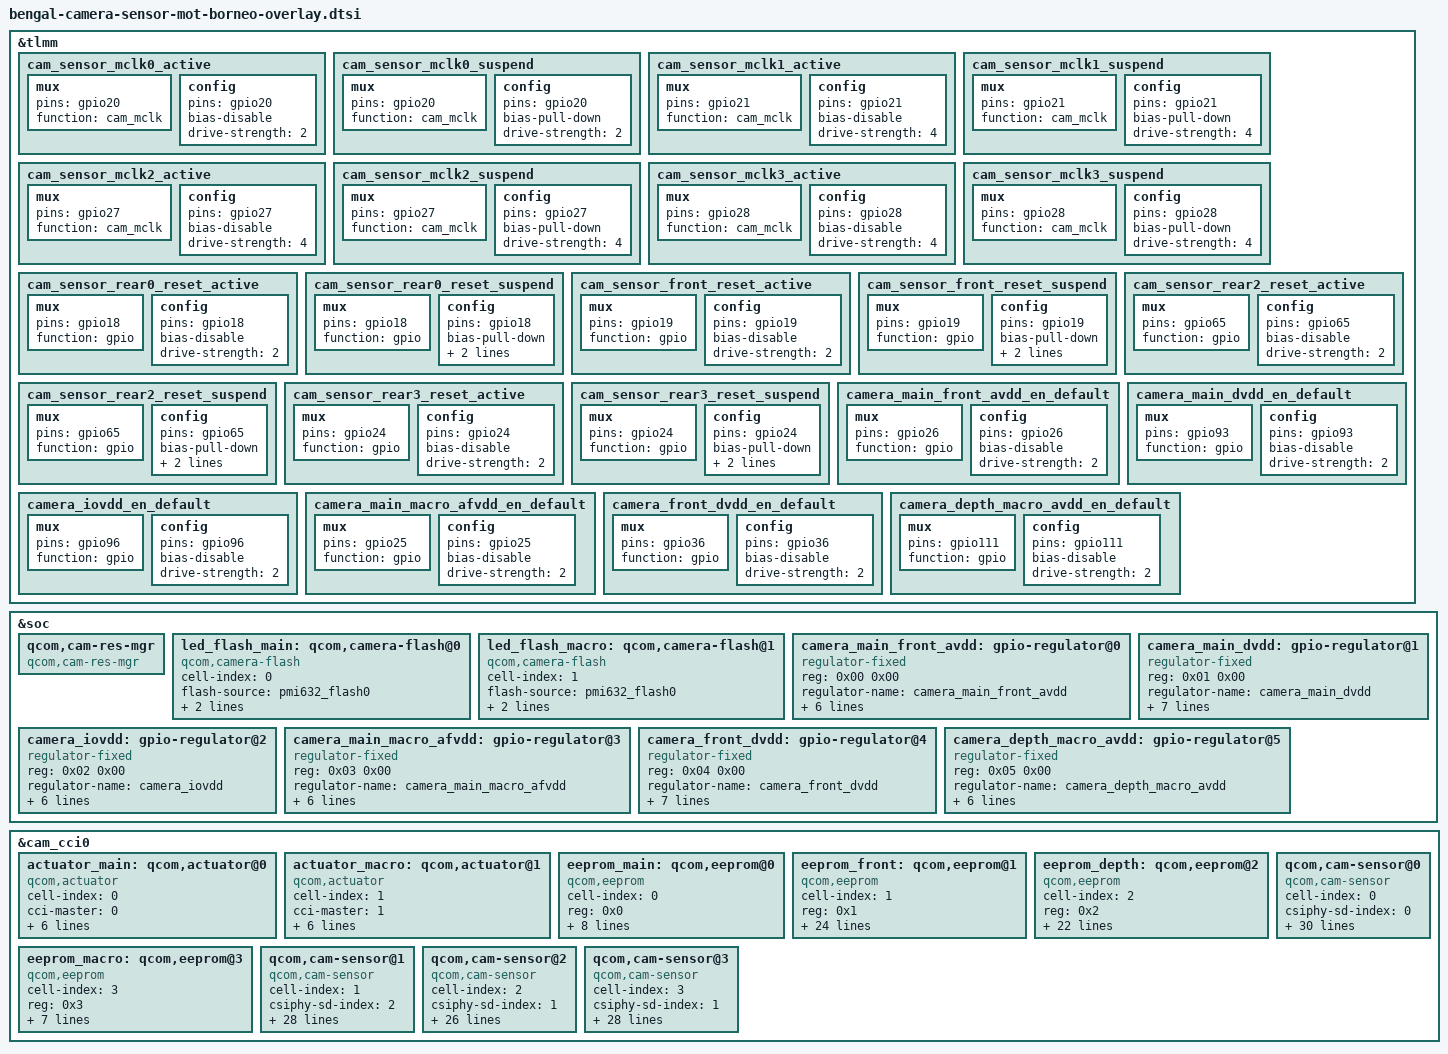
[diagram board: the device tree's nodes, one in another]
#include <dt-bindings/clock/qcom,gcc-bengal.h>

&tlmm {
	cam_sensor_mclk0_active: cam_sensor_mclk0_active {
		/* main mclk*/
		mux {
			pins = "gpio20";
			function = "cam_mclk";
		};

		config {
			pins = "gpio20";
			bias-disable;
			drive-strength = <2>;
		};
	};

	cam_sensor_mclk0_suspend: cam_sensor_mclk0_suspend {
		/* main mclk*/
		mux {
			pins = "gpio20";
			function = "cam_mclk";
		};

		config {
			pins = "gpio20";
			bias-pull-down;
			drive-strength = <2>;
		};
	};

	cam_sensor_mclk1_active: cam_sensor_mclk1_active {
		/* front mclk*/
		mux {
			pins = "gpio21";
			function = "cam_mclk";
		};

		config {
			pins = "gpio21";
			bias-disable;
			drive-strength = <4>;
		};
	};

	cam_sensor_mclk1_suspend: cam_sensor_mclk1_suspend {
		/* front mclk*/
		mux {
			pins = "gpio21";
			function = "cam_mclk";
		};

		config {
			pins = "gpio21";
			bias-pull-down;
			drive-strength = <4>;
		};
	};

	cam_sensor_mclk2_active: cam_sensor_mclk2_active {
		/* macro mclk*/
		mux {
			pins = "gpio27";
			function = "cam_mclk";
		};

		config {
			pins = "gpio27";
			bias-disable;
			drive-strength = <4>;
		};
	};

	cam_sensor_mclk2_suspend: cam_sensor_mclk2_suspend {
		/* macro mclk*/
		mux {
			pins = "gpio27";
			function = "cam_mclk";
		};

		config {
			pins = "gpio27";
			bias-pull-down;
			drive-strength = <4>;
		};
	};

	cam_sensor_mclk3_active: cam_sensor_mclk3_active {
		/* depth mclk*/
		mux {
			pins = "gpio28";
			function = "cam_mclk";
		};

		config {
			pins = "gpio28";
			bias-disable;
			drive-strength = <4>;
		};
	};

	cam_sensor_mclk3_suspend: cam_sensor_mclk3_suspend {
		/* depth mclk*/
		mux {
			pins = "gpio28";
			function = "cam_mclk";
		};

		config {
			pins = "gpio28";
			bias-pull-down;
			drive-strength = <4>;
		};
	};

	cam_sensor_rear0_reset_active: cam_sensor_rear0_reset_active {
		/* main reset*/
		mux {
			pins = "gpio18";
			function = "gpio";
		};

		config {
			pins = "gpio18";
			bias-disable; /* No PULL */
			drive-strength = <2>;
		};
	};

	cam_sensor_rear0_reset_suspend: cam_sensor_rear0_reset_suspend {
		/* main reset*/
		mux {
			pins = "gpio18";
			function = "gpio";
		};

		config {
			pins = "gpio18";
			bias-pull-down; /* PULL DOWN */
			drive-strength = <2>;
			output-low;
		};
	};

	cam_sensor_front_reset_active: cam_sensor_front_reset_active {
		/* front reset*/
		mux {
			pins = "gpio19";
			function = "gpio";
		};

		config {
			pins = "gpio19";
			bias-disable; /* No PULL */
			drive-strength = <2>;
		};
	};

	cam_sensor_front_reset_suspend: cam_sensor_front_reset_suspend {
		/* front reset*/
		mux {
			pins = "gpio19";
			function = "gpio";
		};

		config {
			pins = "gpio19";
			bias-pull-down; /* PULL DOWN */
			drive-strength = <2>;
			output-low;
		};
	};

	cam_sensor_rear2_reset_active: cam_sensor_rear2_reset_active {
		/* depth reset*/
		mux {
			pins = "gpio65";
			function = "gpio";
		};

		config {
			pins = "gpio65";
			bias-disable; /* No PULL */
			drive-strength = <2>;
		};
	};

	cam_sensor_rear2_reset_suspend: cam_sensor_rear2_reset_suspend {
		/* depth reset*/
		mux {
			pins = "gpio65";
			function = "gpio";
		};

		config {
			pins = "gpio65";
			bias-pull-down; /* PULL DOWN */
			drive-strength = <2>;
			output-low;
		};
	};

	cam_sensor_rear3_reset_active: cam_sensor_rear3_reset_active {
		/* macro reset*/
		mux {
			pins = "gpio24";
			function = "gpio";
		};

		config {
			pins = "gpio24";
			bias-disable; /* No PULL */
			drive-strength = <2>;
		};
	};

	cam_sensor_rear3_reset_suspend: cam_sensor_rear3_reset_suspend {
		/* macro reset*/
		mux {
			pins = "gpio24";
			function = "gpio";
		};

		config {
			pins = "gpio24";
			bias-pull-down; /* PULL DOWN */
			drive-strength = <2>;
			output-low;
		};
	};

	camera_main_front_avdd_en_default: camera_main_front_avdd_en_default {
		mux {
			pins = "gpio26";
			function = "gpio";
		};

		config {
			pins = "gpio26";
			bias-disable; /* No PULL */
			drive-strength = <2>; /* 2 MA */
		};
	};

	camera_main_dvdd_en_default: camera_main_dvdd_en_default {
		mux {
			pins = "gpio93";
			function = "gpio";
		};

		config {
			pins = "gpio93";
			bias-disable; /* No PULL */
			drive-strength = <2>; /* 2 MA */
		};
	};

	camera_iovdd_en_default: camera_iovdd_en_default {
		mux {
			pins = "gpio96";
			function = "gpio";
		};

		config {
			pins = "gpio96";
			bias-disable; /* No PULL */
			drive-strength = <2>; /* 2 MA */
		};
	};

	camera_main_macro_afvdd_en_default: camera_main_macro_afvdd_en_default {
		mux {
			pins = "gpio25";
			function = "gpio";
		};

		config {
			pins = "gpio25";
			bias-disable; /* No PULL */
			drive-strength = <2>; /* 2 MA */
		};
	};

	camera_front_dvdd_en_default: camera_front_dvdd_en_default {
		mux {
			pins = "gpio36";
			function = "gpio";
		};

		config {
			pins = "gpio36";
			bias-disable; /* No PULL */
			drive-strength = <2>; /* 2 MA */
		};
	};

	camera_depth_macro_avdd_en_default: camera_depth_macro_avdd_en_default {
		mux {
			pins = "gpio111";
			function = "gpio";
		};

		config {
			pins = "gpio111";
			bias-disable; /* No PULL */
			drive-strength = <2>; /* 2 MA */
		};
	};
};

&soc {
	qcom,cam-res-mgr {
		compatible = "qcom,cam-res-mgr";
		status = "ok";
	};

	led_flash_main: qcom,camera-flash@0 {
		cell-index = <0>;
		compatible = "qcom,camera-flash";
		flash-source  = <&pmi632_flash0>;
		torch-source  = <&pmi632_torch0>;
		switch-source = <&pmi632_switch0>;
		status = "ok";
	};

	led_flash_macro: qcom,camera-flash@1 {
		cell-index = <1>;
		compatible = "qcom,camera-flash";
		flash-source  = <&pmi632_flash0>;
		torch-source  = <&pmi632_torch0>;
		switch-source = <&pmi632_switch0>;
		status = "ok";
	};

	camera_main_front_avdd: gpio-regulator@0 {
		compatible = "regulator-fixed";
		reg = <0x00 0x00>;
		regulator-name = "camera_main_front_avdd";
		regulator-min-microvolt = <2800000>;
		regulator-max-microvolt = <2800000>;
		regulator-enable-ramp-delay = <233>;
		enable-active-high;
		gpio = <&tlmm 26 0>;
		pinctrl-names = "default";
		pinctrl-0 = <&camera_main_front_avdd_en_default>;
	};

	camera_main_dvdd: gpio-regulator@1 {
		compatible = "regulator-fixed";
		reg = <0x01 0x00>;
		regulator-name = "camera_main_dvdd";
		regulator-min-microvolt = <1050000>;
		regulator-max-microvolt = <1050000>;
		regulator-enable-ramp-delay = <233>;
		enable-active-high;
		gpio = <&tlmm 93 0>;
		pinctrl-names = "default";
		pinctrl-0 = <&camera_main_dvdd_en_default>;
		vin-supply = <&S6A>;
	};

	camera_iovdd: gpio-regulator@2 {
		compatible = "regulator-fixed";
		reg = <0x02 0x00>;
		regulator-name = "camera_iovdd";
		regulator-min-microvolt = <1800000>;
		regulator-max-microvolt = <1800000>;
		regulator-enable-ramp-delay = <233>;
		enable-active-high;
		gpio = <&tlmm 96 0>;
		pinctrl-names = "default";
		pinctrl-0 = <&camera_iovdd_en_default>;
	};

	camera_main_macro_afvdd: gpio-regulator@3 {
		compatible = "regulator-fixed";
		reg = <0x03 0x00>;
		regulator-name = "camera_main_macro_afvdd";
		regulator-min-microvolt = <2800000>;
		regulator-max-microvolt = <2800000>;
		regulator-enable-ramp-delay = <233>;
		enable-active-high;
		gpio = <&tlmm 25 0>;
		pinctrl-names = "default";
		pinctrl-0 = <&camera_main_macro_afvdd_en_default>;
	};

	camera_front_dvdd: gpio-regulator@4 {
		compatible = "regulator-fixed";
		reg = <0x04 0x00>;
		regulator-name = "camera_front_dvdd";
		regulator-min-microvolt = <1200000>;
		regulator-max-microvolt = <1200000>;
		regulator-enable-ramp-delay = <233>;
		enable-active-high;
		gpio = <&tlmm 36 0>;
		pinctrl-names = "default";
		pinctrl-0 = <&camera_front_dvdd_en_default>;
		vin-supply = <&S6A>;
	};

	camera_depth_macro_avdd: gpio-regulator@5 {
		compatible = "regulator-fixed";
		reg = <0x05 0x00>;
		regulator-name = "camera_depth_macro_avdd";
		regulator-min-microvolt = <2800000>;
		regulator-max-microvolt = <2800000>;
		regulator-enable-ramp-delay = <233>;
		enable-active-high;
		gpio = <&tlmm 111 0>;
		pinctrl-names = "default";
		pinctrl-0 = <&camera_depth_macro_avdd_en_default>;
	};
};

&cam_cci0 {
	actuator_main: qcom,actuator@0 {
		cell-index = <0>;
		compatible = "qcom,actuator";
		cci-master = <0>;
		cam_vaf-supply = <&camera_main_macro_afvdd>;
		regulator-names = "cam_vaf";
		rgltr-cntrl-support;
		rgltr-min-voltage = <2800000>;
		rgltr-max-voltage = <2800000>;
		rgltr-load-current = <100000>;
		status = "ok";
	};

	actuator_macro: qcom,actuator@1 {
		cell-index = <1>;
		compatible = "qcom,actuator";
		cci-master = <1>;
		cam_vaf-supply = <&camera_main_macro_afvdd>;
		regulator-names = "cam_vaf";
		rgltr-cntrl-support;
		rgltr-min-voltage = <2800000>;
		rgltr-max-voltage = <2800000>;
		rgltr-load-current = <100000>;
		status = "ok";
	};

	eeprom_main: qcom,eeprom@0 {
		cell-index = <0>;
		reg = <0x0>;
		compatible = "qcom,eeprom";
		cci-master = <0>;
		cam_vaf-supply = <&camera_main_macro_afvdd>;
		cam_vio-supply = <&camera_iovdd>;
		regulator-names = "cam_vaf", "cam_vio";
		rgltr-cntrl-support;
		rgltr-min-voltage = <2800000 1800000>;
		rgltr-max-voltage = <2800000 1800000>;
		rgltr-load-current = <100000 120000>;
		status = "ok";
	};

	eeprom_front: qcom,eeprom@1 {
		cell-index = <1>;
		reg = <0x1>;
		compatible = "qcom,eeprom";
		cam_vio-supply = <&camera_iovdd>;
		cam_vana-supply = <&camera_main_front_avdd>;
		cam_vdig-supply = <&camera_front_dvdd>;
		cam_clk-supply = <&gcc_camss_top_gdsc>;
		regulator-names = "cam_vio", "cam_vana", "cam_vdig",
			"cam_clk";
		rgltr-cntrl-support;
		rgltr-min-voltage = <1800000 2800000 1200000 0>;
		rgltr-max-voltage = <1800000 2800000 1200000 0>;
		rgltr-load-current = <120000 80000 1200000 0>;
		gpio-no-mux = <0>;
		pinctrl-names = "cam_default", "cam_suspend";
		pinctrl-0 = <&cam_sensor_mclk1_active
				&cam_sensor_front_reset_active>;
		pinctrl-1 = <&cam_sensor_mclk1_suspend
				&cam_sensor_front_reset_suspend>;
		gpios = <&tlmm 21 0>,
			<&tlmm 19 0>;
		gpio-reset = <1>;
		gpio-req-tbl-num = <0 1>;
		gpio-req-tbl-flags = <1 0>;
		gpio-req-tbl-label = "CAMIF_MCLK1",
					"CAM_RESET1";
		cci-master = <0>;
		status = "ok";
		clocks = <&gcc GCC_CAMSS_MCLK1_CLK>;
		clock-names = "cam_clk";
		clock-cntl-level = "turbo";
		clock-rates = <24000000>;
	};

	eeprom_depth: qcom,eeprom@2 {
		cell-index = <2>;
		reg = <0x2>;
		compatible = "qcom,eeprom";
		cci-master = <1>;
		cam_vio-supply = <&camera_iovdd>;
		cam_vana-supply = <&camera_depth_macro_avdd>;
		cam_clk-supply = <&gcc_camss_top_gdsc>;
		regulator-names = "cam_vio", "cam_vana", "cam_clk";
		rgltr-cntrl-support;
		rgltr-min-voltage = <1800000 2800000 0>;
		rgltr-max-voltage = <1800000 2800000 0>;
		rgltr-load-current = <120000 80000 0>;
		gpio-no-mux = <0>;
		pinctrl-names = "cam_default", "cam_suspend";
		pinctrl-0 = <&cam_sensor_mclk3_active
				&cam_sensor_rear2_reset_active>;
		pinctrl-1 = <&cam_sensor_mclk3_suspend
				&cam_sensor_rear2_reset_suspend>;
		gpios = <&tlmm 28 0>,
			<&tlmm 65 0>;
		gpio-reset = <1>;
		gpio-req-tbl-num = <0 1>;
		gpio-req-tbl-flags = <1 0>;
		gpio-req-tbl-label = "CAMIF_MCLK3",
					"CAM_PWDN";
		status = "ok";
		clocks = <&gcc GCC_CAMSS_MCLK3_CLK>;
		clock-names = "cam_clk";
		clock-cntl-level = "turbo";
		clock-rates = <24000000>;
	};

	eeprom_macro: qcom,eeprom@3 {
		cell-index = <3>;
		reg = <0x3>;
		compatible = "qcom,eeprom";
		cci-master = <1>;
		cam_vio-supply = <&camera_iovdd>;
		regulator-names = "cam_vio";
		rgltr-cntrl-support;
		rgltr-min-voltage = <1800000>;
		rgltr-max-voltage = <1800000>;
		rgltr-load-current = <120000>;
		status = "ok";
	};

	qcom,cam-sensor@0 {
		cell-index = <0>;
		compatible = "qcom,cam-sensor";
		csiphy-sd-index = <0>;
		sensor-position-roll = <90>;
		sensor-position-pitch = <0>;
		sensor-position-yaw = <180>;
		actuator-src = <&actuator_main>;
		led-flash-src = <&led_flash_main>;
		eeprom-src = <&eeprom_main>;
		cam_vio-supply = <&camera_iovdd>;
		cam_vana-supply = <&camera_main_front_avdd>;
		cam_vdig-supply = <&camera_main_dvdd>;
		cam_clk-supply = <&gcc_camss_top_gdsc>;
		regulator-names = "cam_vio", "cam_vana", "cam_vdig",
			"cam_clk";
		rgltr-cntrl-support;
		rgltr-min-voltage = <1800000 2800000 1050000 0>;
		rgltr-max-voltage = <1800000 2800000 1050000 0>;
		rgltr-load-current = <120000 80000 1200000 0>;
		gpio-no-mux = <0>;
		pinctrl-names = "cam_default", "cam_suspend";
		pinctrl-0 = <&cam_sensor_mclk0_active
				&cam_sensor_rear0_reset_active>;
		pinctrl-1 = <&cam_sensor_mclk0_suspend
				&cam_sensor_rear0_reset_suspend>;
		gpios = <&tlmm 20 0>,
			<&tlmm 18 0>;
		gpio-reset = <1>;
		gpio-req-tbl-num = <0 1>;
		gpio-req-tbl-flags = <1 0>;
		gpio-req-tbl-label = "CAMIF_MCLK0",
					"CAM_RESET0";
		cci-master = <0>;
		status = "ok";
		clocks = <&gcc GCC_CAMSS_MCLK0_CLK>;
		clock-names = "cam_clk";
		clock-cntl-level = "turbo";
		clock-rates = <24000000>;
	};

	qcom,cam-sensor@1 {
		cell-index = <1>;
		compatible = "qcom,cam-sensor";
		csiphy-sd-index = <2>;
		sensor-position-roll = <270>;
		sensor-position-pitch = <0>;
		sensor-position-yaw = <0>;
		eeprom-src = <&eeprom_front>;
		cam_vio-supply = <&camera_iovdd>;
		cam_vana-supply = <&camera_main_front_avdd>;
		cam_vdig-supply = <&camera_front_dvdd>;
		cam_clk-supply = <&gcc_camss_top_gdsc>;
		regulator-names = "cam_vio", "cam_vana", "cam_vdig",
			"cam_clk";
		rgltr-cntrl-support;
		rgltr-min-voltage = <1800000 2800000 1200000 0>;
		rgltr-max-voltage = <1800000 2800000 1200000 0>;
		rgltr-load-current = <120000 80000 1200000 0>;
		gpio-no-mux = <0>;
		pinctrl-names = "cam_default", "cam_suspend";
		pinctrl-0 = <&cam_sensor_mclk1_active
				&cam_sensor_front_reset_active>;
		pinctrl-1 = <&cam_sensor_mclk1_suspend
				&cam_sensor_front_reset_suspend>;
		gpios = <&tlmm 21 0>,
			<&tlmm 19 0>;
		gpio-reset = <1>;
		gpio-req-tbl-num = <0 1>;
		gpio-req-tbl-flags = <1 0>;
		gpio-req-tbl-label = "CAMIF_MCLK1",
					"CAM_RESET1";
		cci-master = <0>;
		status = "ok";
		clocks = <&gcc GCC_CAMSS_MCLK1_CLK>;
		clock-names = "cam_clk";
		clock-cntl-level = "turbo";
		clock-rates = <24000000>;
	};

	qcom,cam-sensor@2 {
		cell-index = <2>;
		compatible = "qcom,cam-sensor";
		csiphy-sd-index = <1>;
		sensor-position-roll = <90>;
		sensor-position-pitch = <0>;
		sensor-position-yaw = <180>;
		eeprom-src = <&eeprom_depth>;
		cam_vio-supply = <&camera_iovdd>;
		cam_vana-supply = <&camera_depth_macro_avdd>;
		cam_clk-supply = <&gcc_camss_top_gdsc>;
		regulator-names = "cam_vio", "cam_vana", "cam_clk";
		rgltr-cntrl-support;
		rgltr-min-voltage = <1800000 2800000 0>;
		rgltr-max-voltage = <1800000 2800000 0>;
		rgltr-load-current = <120000 80000 0>;
		gpio-no-mux = <0>;
		pinctrl-names = "cam_default", "cam_suspend";
		pinctrl-0 = <&cam_sensor_mclk3_active
				&cam_sensor_rear2_reset_active>;
		pinctrl-1 = <&cam_sensor_mclk3_suspend
				&cam_sensor_rear2_reset_suspend>;
		gpios = <&tlmm 28 0>,
			<&tlmm 65 0>;
		gpio-reset = <1>;
		gpio-req-tbl-num = <0 1>;
		gpio-req-tbl-flags = <1 0>;
		gpio-req-tbl-label = "CAMIF_MCLK3",
					"CAM_PWDN";
		cci-master = <1>;
		status = "ok";
		clocks = <&gcc GCC_CAMSS_MCLK3_CLK>;
		clock-names = "cam_clk";
		clock-cntl-level = "turbo";
		clock-rates = <24000000>;
	};

	qcom,cam-sensor@3 {
		cell-index = <3>;
		compatible = "qcom,cam-sensor";
		csiphy-sd-index = <1>;
		sensor-position-roll = <90>;
		sensor-position-pitch = <0>;
		sensor-position-yaw = <180>;
		actuator-src = <&actuator_macro>;
		led-flash-src = <&led_flash_macro>;
		eeprom-src = <&eeprom_macro>;
		cam_vio-supply = <&camera_iovdd>;
		cam_vana-supply = <&camera_depth_macro_avdd>;
		cam_clk-supply = <&gcc_camss_top_gdsc>;
		regulator-names = "cam_vio", "cam_vana", "cam_clk";
		rgltr-cntrl-support;
		rgltr-min-voltage = <1800000 2800000 0>;
		rgltr-max-voltage = <1800000 2800000 0>;
		rgltr-load-current = <120000 80000 0>;
		gpio-no-mux = <0>;
		pinctrl-names = "cam_default", "cam_suspend";
		pinctrl-0 = <&cam_sensor_mclk2_active
				&cam_sensor_rear3_reset_active>;
		pinctrl-1 = <&cam_sensor_mclk2_suspend
				&cam_sensor_rear3_reset_suspend>;
		gpios = <&tlmm 27 0>,
			<&tlmm 24 0>;
		gpio-reset = <1>;
		gpio-req-tbl-num = <0 1>;
		gpio-req-tbl-flags = <1 0>;
		gpio-req-tbl-label = "CAMIF_MCLK2",
					"CAM_PWDN2";
		cci-master = <1>;
		status = "ok";
		clocks = <&gcc GCC_CAMSS_MCLK2_CLK>;
		clock-names = "cam_clk";
		clock-cntl-level = "turbo";
		clock-rates = <24000000>;
	};
};
